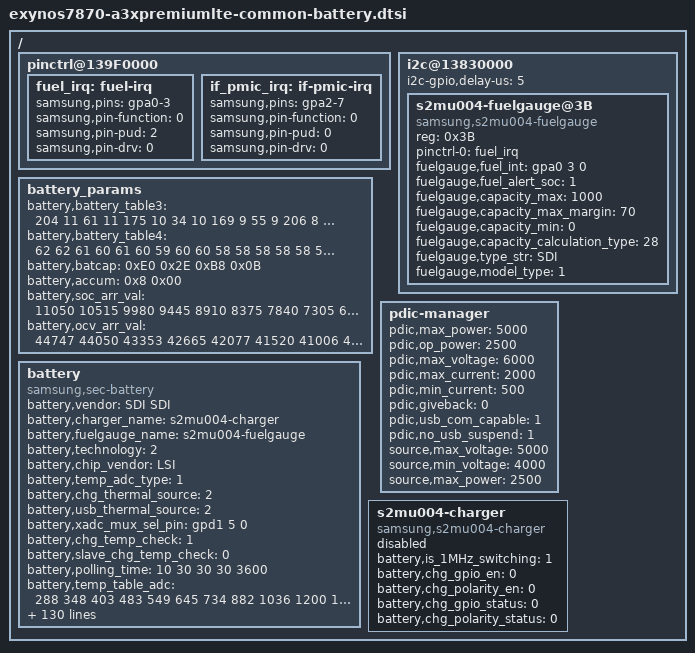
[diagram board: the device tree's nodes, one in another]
/*
 * Copyright (c) 2016 Samsung Electronics Co., Ltd.
 *		http://www.samsung.com
 *
 * This program is free software; you can redistribute it and/or modify
 * it under the terms of the GNU General Public License version 2 as
 * published by the Free Software Foundation.
*/

/ {
	pinctrl@139F0000 {
		fuel_irq: fuel-irq {
			samsung,pins = "gpa0-3";
			samsung,pin-function = <0>;
			samsung,pin-pud = <2>;
			samsung,pin-drv = <0>;
		};

		if_pmic_irq: if-pmic-irq {
			samsung,pins = "gpa2-7";
			samsung,pin-function = <0>;
			samsung,pin-pud = <0>;
			samsung,pin-drv = <0>;
		};
	};

	i2c@13830000 {
		i2c-gpio,delay-us = <5>;
		status = "okay";
		s2mu004-fuelgauge@3B {
			compatible = "samsung,s2mu004-fuelgauge";
			reg = <0x3B>;
			pinctrl-names = "default";
			pinctrl-0 = <&fuel_irq>;
			fuelgauge,fuel_int = <&gpa0 3 0>;
			fuelgauge,fuel_alert_soc = <1>;
			fuelgauge,capacity_max = <1000>;
			fuelgauge,capacity_max_margin = <70>;
			fuelgauge,capacity_min = <0>;
			fuelgauge,capacity_calculation_type = <28>;
			fuelgauge,type_str = "SDI";
			fuelgauge,model_type = <1>;
		};
	};

	battery_params {
			battery,battery_table3 = <204 11 61 11 175 10 34 10 169 9
						55 9 206 8 107 8 230 7 166 7
						77 7 235 6 174 6 130 6 95 6
						67 6 36 6 253 5 197 5 147 5
						42 5 168 1 215 8 105 8 252 7
						142 7 33 7 179 6 70 6 216 5
						106 5 253 4 143 4 34 4 180 3
						70 3 217 2 107 2 254 1 144 1
						35 1 181 0 71 0 218 15>;

			battery,battery_table4 = <62 62 61 60 61 60 59 60 60 58
						58 58 58 58 58 58 59 60 62 64
						76 154>;

			battery,batcap = <0xE0 0x2E 0xB8 0x0B>; /* [0x0E] [0x0F] [0x10] [0x11] */
			battery,accum = <0x8 0x00>; /* [0x45] [0x44] */

			battery,soc_arr_val = <11050 10515 9980 9445 8910 8375 7840 7305 6770 6235 5700 5165 4629 4094 3559 3024 2489 1954 1419 884 349 (-186)>;
			battery,ocv_arr_val = <44747 44050 43353 42665 42077 41520 41006 40523 39872 39563 39127 38646 38349 38135 37966 37828 37676 37485 37211 36970 36454 32069>;
	};

	pdic-manager {
		/* sink */
		pdic,max_power = <5000>;
		pdic,op_power = <2500>;
		pdic,max_voltage = <6000>;
		pdic,max_current = <2000>;
		pdic,min_current = <500>;

		pdic,giveback = <0>;
		pdic,usb_com_capable = <1>;
		pdic,no_usb_suspend = <1>;

		/* source */
		source,max_voltage = <5000>;
		source,min_voltage = <4000>;
		source,max_power = <2500>;
	};

	battery {
		status = "okay";
		compatible = "samsung,sec-battery";

		pinctrl-names = "default";

		battery,vendor = "SDI SDI";
		battery,charger_name = "s2mu004-charger";
		battery,fuelgauge_name = "s2mu004-fuelgauge";
		battery,technology = <2>; /* POWER_SUPPLY_TECHNOLOGY_LION */

		battery,chip_vendor = "LSI";
		battery,temp_adc_type = <1>; /* SEC_BATTERY_ADC_TYPE_AP */

		battery,chg_thermal_source = <2>; /* SEC_CHARGER_THERMAL_SOURCE_FG */
		battery,usb_thermal_source = <2>; /* SEC_BATTERY_THERMAL_SOURCE_ADC */
		battery,xadc_mux_sel_pin = <&gpd1 5 0>;	/* low : BAT_THM, high : USB_THM */
		battery,chg_temp_check = <1>;
		battery,slave_chg_temp_check = <0>;

		battery,polling_time = <10 30 30 30 3600>;

		battery,temp_table_adc = <288 348 403 483 549 645 734 882 1036 1200 1378 1589 1773 2018
								2259 2500 2715 2928 3113 3278 3381 3519 3616>;
		battery,temp_table_data = <900 850 800 750 700 650 600 550 500 450 400 350 300 250
								200 150 100 50 0 (-50) (-100) (-150) (-200)>;
								
		battery,usb_temp_table_adc = <288 340 399 490 551 646 757 888 1026 1167 1377 1577 1773 2029
								2270 2496 2723 2931 3112 3287 3444 3561 3659>;
		battery,usb_temp_table_data = <900 850 800 750 700 650 600 550 500 460 400 350 300 250
								200 150 100 50 0 (-50) (-100) (-150) (-200)>;

		battery,input_current_limit = <1800 450 450 1800 500 900 1800 450 1000 450 900 900 900 1900 1800 450 450 400 700 1300 300 1000 1800 450 1650 2100 1000 1650 80 1800 1650 1400 1000 1000 700 900 900 900 500 1800 1600 3000>;
		battery,fast_charging_current = <1700 450 450 1700 800 1200 1500 450 1200 450 1700 1700 1700 1600 1700 450 450 400 700 1300 300 1000 1500 450 2160 3500 1000 3000 80 1800 1000 1400 450 1000 1700 1700 1700 1700 450 3000 3000 3000>;
		battery,full_check_current_1st = <300 0 0 300 300 300 300 300 300 0 300 300 300 300 300 0 0 300 300 300 300 300 300 0 300 300 300 300 0 300 300 300 0 300 300 300 300 300 300 300 300 300>;
		battery,full_check_current_2nd = <100 0 0 100 100 100 100 100 100 0 100 100 100 100 100 0 0 100 100 100 100 100 100 0 100 100 100 100 0 100 100 100 0 100 100 100 100 100 100 100 100 100>;

		battery,wireless_cc_cv = <85>;
		battery,inbat_voltage = <1>;

		battery,inbat_voltage_table_adc = <2878 2861 2827 2801 2770 2742 2709 2685 2651 2628
						2601 2563 2539 2508 2478 2447 2425 2392 2369 2338 2306>;
		battery,inbat_voltage_table_data = <4380 4350 4300 4250 4200 4150 4100 4050 4000 3950
						3900 3850 3800 3750 3700 3650 3600 3550 3500 3450 3400>;

		battery,adc_check_count = <5>;

		battery,cable_check_type = <4>; /* SEC_BATTERY_CABLE_CHECK_PSY */
		battery,cable_source_type = <1>; /* SEC_BATTERY_CABLE_SOURCE_EXTERNAL */
		battery,polling_type = <1>; /* SEC_BATTERY_MONITOR_ALARM */
		battery,monitor_initial_count = <0>;

		battery,battery_check_type = <0>; /* SEC_BATTERY_CHECK_NONE */
		battery,check_count = <0>;
		battery,check_adc_max = <1440>;
		battery,check_adc_min = <0>;

		battery,ovp_uvlo_check_type = <3>; /* SEC_BATTERY_OVP_UVLO_CHGPOLLING */

		battery,thermal_source = <2>; /* SEC_BATTERY_THERMAL_SOURCE_ADC */

		battery,temp_check_type = <2>; /* SEC_BATTERY_TEMP_CHECK_TEMP */
		battery,temp_check_count = <1>;
		battery,temp_highlimit_threshold_normal = <800>;
		battery,temp_highlimit_recovery_normal = <750>;
		battery,temp_high_threshold_normal = <500>;
		battery,temp_high_recovery_normal = <450>;
		battery,temp_low_threshold_normal = <0>;
		battery,temp_low_recovery_normal = <50>;
		battery,temp_highlimit_threshold_lpm = <800>;
		battery,temp_highlimit_recovery_lpm = <750>;
		battery,temp_high_threshold_lpm = <500>;
		battery,temp_high_recovery_lpm = <450>;
		battery,temp_low_threshold_lpm = <0>;
		battery,temp_low_recovery_lpm = <50>;

		battery,full_check_type = <2>; /* SEC_BATTERY_FULLCHARGED_FG_CURRENT */
		battery,full_check_type_2nd = <2>; /* SEC_BATTERY_FULLCHARGED_FG_CURRENT */
		battery,full_check_count = <1>;
		battery,chg_gpio_full_check = <0>;
		battery,chg_polarity_full_check = <1>;

		battery,chg_12v_high_temp = <615>;
		battery,chg_high_temp = <500>;
		battery,chg_high_temp_recovery = <495>;
		/* battery,chg_charging_limit_current = <1300>; */

		battery,wpc_high_temp = <460 495>;
		battery,wpc_high_temp_recovery = <459 400>;
		battery,wpc_charging_limit_current = <540 400>;
		battery,wpc_heat_temp_recovery = <360>;
		battery,wpc_lcd_on_high_temp = <470>;
		battery,wpc_lcd_on_high_temp_rec = <300>;
		battery,wpc_hv_lcd_on_input_limit_current = <400>;

		battery,sleep_mode_limit_current = <500>;
		battery,wc_full_input_limit_current = <100>;
		battery,wc_heating_input_limit_current = <400>;
		battery,wc_heating_time = <300>; /* 5 min */
		battery,wc_cv_current = <820>;
		battery,wc_cv_pack_current = <630>;

		battery,mix_high_temp = <420>;
		battery,mix_high_chg_temp = <500>;
		battery,mix_high_temp_recovery = <390>;

		/* SEC_BATTERY_FULL_CONDITION_SOC |
		   SEC_BATTERY_FULL_CONDITION_NOTIMEFULL |
		   SEC_BATTERY_FULL_CONDITION_VCELL */
		battery,full_condition_type = <13>;
		battery,full_condition_soc = <93>;
		battery,full_condition_vcell = <4270>;

		battery,recharge_check_count = <1>;
		battery,recharge_condition_type = <4>; /* SEC_BATTERY_RECHARGE_CONDITION_VCELL */
		battery,recharge_condition_soc = <98>;
		battery,recharge_condition_vcell = <4300>;

		battery,charging_total_time = <21600>;
		battery,recharging_total_time = <5400>;
		battery,charging_reset_time = <0>;

		battery,chg_float_voltage = <4350>;

		battery,swelling_high_temp_block = <410>;
		battery,swelling_high_temp_recov = <360>;
		battery,swelling_low_temp_block = <100>;
		battery,swelling_low_temp_recov = <150>;
		battery,swelling_low_temp_additional = <50>;

		battery,swelling_low_temp_current = <1080>;
		battery,swelling_low_temp_additional_current = <350>;
		battery,swelling_low_temp_topoff = <150>;
		battery,swelling_high_temp_current = <1080>;
		battery,swelling_high_temp_topoff = <150>;

		battery,swelling_drop_float_voltage = <4150>;
		battery,swelling_high_rechg_voltage = <4100>;
		battery,swelling_low_rechg_voltage = <4000>;

		battery,self_discharging_temp_block = <600>;
		battery,self_discharging_volt_block = <4250>;
		battery,self_discharging_temp_recov = <550>;
		battery,self_discharging_temp_pollingtime = <400>;

		battery,siop_event_check_type = <1>;
		battery,siop_call_cv_current = <330>;
		battery,siop_call_cc_current = <330>;

		battery,siop_input_limit_current = <1200>;
		battery,siop_charging_limit_current = <1000>;
		battery,siop_hv_input_limit_current = <700>;
		battery,siop_hv_charging_limit_current = <1000>;
		battery,siop_hv_12v_input_limit_current = <535>;
		battery,siop_hv_12v_charging_limit_current = <1000>;

		battery,siop_wireless_input_limit_current = <600>;
		battery,siop_wireless_charging_limit_current = <1000>;
		battery,siop_hv_wireless_input_limit_current = <600>;
		battery,siop_hv_wireless_charging_limit_current = <1000>;

                battery,ttf_hv_12v_charge_current = <2350>;
		battery,ttf_hv_charge_current = <2200>;
		battery,ttf_hv_wireless_charge_current = <1500>;

		/* cycle, chg_float_voltage, recharge_condition_vcell, full_condition_vcell, full_condition_soc */
		battery,age_data = <0 43625 4312 4275 93
				300 43250 4275 4210 89
				500 42875 4237 4170 85>;

		/* values for using CONFIG_STEP_CHARGING */
		battery,step_charging_type = <0x5>;
		battery,step_charging_charge_power = <20000>;
		battery,step_charging_condtion = <4100 4400>;
		battery,step_charging_current = <4200 3000>;
		/* values for not using CONFIG_STEP_CHARGING */
		battery,base_charge_power = <15000>;
		battery,max_charging_current = <3000>;

		battery,max_input_voltage = <9000>; /* mV */
		battery,max_input_current = <3000>;  /* mA */

		io-channels = <&exynos_adc 1>, <&exynos_adc 3>;
		io-channel-names = "adc-temp", "adc-in-bat";
		#io-channel-cells = <5>;
		io-channel-ranges;
	};

	s2mu004-charger {
		status = "disable";
		compatible = "samsung,s2mu004-charger";
		battery,is_1MHz_switching = <1>;
		battery,chg_gpio_en = <0>;
		battery,chg_polarity_en = <0>;
		battery,chg_gpio_status = <0>;
		battery,chg_polarity_status = <0>;
	};

};
